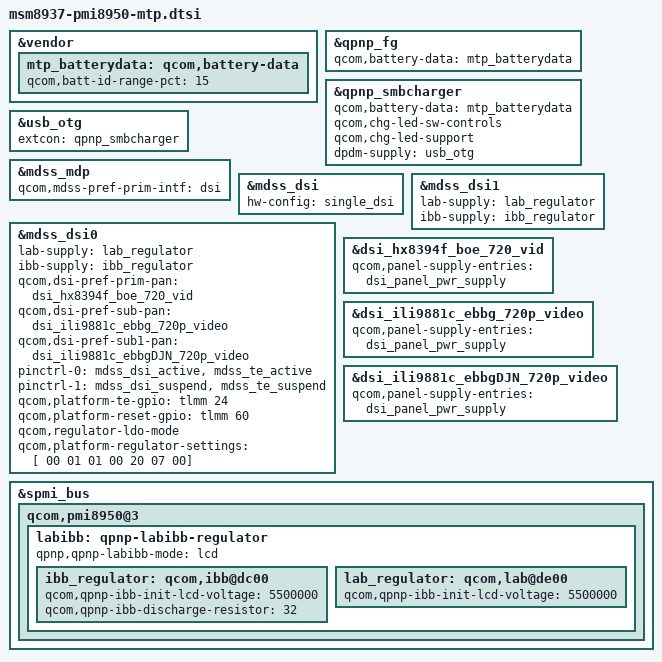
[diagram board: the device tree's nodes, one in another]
/*
 * Copyright (c) 2015-2016, 2018, The Linux Foundation. All rights reserved.
 * Copyright (C) 2018 XiaoMi, Inc.
 *
 * This program is free software; you can redistribute it and/or modify
 * it under the terms of the GNU General Public License version 2 and
 * only version 2 as published by the Free Software Foundation.
 *
 * This program is distributed in the hope that it will be useful,
 * but WITHOUT ANY WARRANTY; without even the implied warranty of
 * MERCHANTABILITY or FITNESS FOR A PARTICULAR PURPOSE.  See the
 * GNU General Public License for more details.
 */

#include "pmi8950.dtsi"
#include "msm8937-mtp.dtsi"
#include "dsi-panel-hx8394f-boe-720p-video.dtsi"
#include "dsi-panel-ili9881c-ebbg-720p-video.dtsi"
#include "dsi-panel-ili9881c-ebbgDJN-720p-video.dtsi"

&vendor {
	mtp_batterydata: qcom,battery-data {
		qcom,batt-id-range-pct = <15>;
		#include "batterydata-itech-3000mah.dtsi"
		#include "batterydata-ascent-3450mAh.dtsi"
	};
};

&qpnp_fg {
	qcom,battery-data = <&mtp_batterydata>;
};

&qpnp_smbcharger {
	qcom,battery-data = <&mtp_batterydata>;
	qcom,chg-led-sw-controls;
	qcom,chg-led-support;
	dpdm-supply = <&usb_otg>;
};

&usb_otg {
	extcon = <&qpnp_smbcharger>;
};

&labibb {
	status = "ok";
	qpnp,qpnp-labibb-mode = "lcd";
};

&ibb_regulator {
	qcom,qpnp-ibb-discharge-resistor = <32>;
};

&mdss_mdp {
	qcom,mdss-pref-prim-intf = "dsi";
};

&mdss_dsi {
	hw-config = "single_dsi";
};

&mdss_dsi0 {
	lab-supply = <&lab_regulator>;
	ibb-supply = <&ibb_regulator>;
	
	qcom,dsi-pref-prim-pan = <&dsi_hx8394f_boe_720_vid>;
	qcom,dsi-pref-sub-pan = <&dsi_ili9881c_ebbg_720p_video>;
	qcom,dsi-pref-sub1-pan = <&dsi_ili9881c_ebbgDJN_720p_video>;
	pinctrl-names = "mdss_default", "mdss_sleep";
	pinctrl-0 = <&mdss_dsi_active &mdss_te_active>;
	pinctrl-1 = <&mdss_dsi_suspend &mdss_te_suspend>;

	qcom,platform-te-gpio = <&tlmm 24 0>;
	qcom,platform-reset-gpio = <&tlmm 60 0>;

	qcom,regulator-ldo-mode;
	qcom,platform-regulator-settings = [ 00 01 01 00 20 07 00];
};

&mdss_dsi1 {
	lab-supply = <&lab_regulator>;
	ibb-supply = <&ibb_regulator>;
};

&dsi_hx8394f_boe_720_vid {
	qcom,panel-supply-entries = <&dsi_panel_pwr_supply>;
};

&dsi_ili9881c_ebbg_720p_video {
	qcom,panel-supply-entries = <&dsi_panel_pwr_supply>;
};
&dsi_ili9881c_ebbgDJN_720p_video {
	qcom,panel-supply-entries = <&dsi_panel_pwr_supply>;
};

&spmi_bus {
	qcom,pmi8950@3 {
		labibb: qpnp-labibb-regulator {
			ibb_regulator: qcom,ibb@dc00 {
				/delete-property/
					qcom,qpnp-ibb-use-default-voltage;
				qcom,qpnp-ibb-init-lcd-voltage = <5500000>;
			};

			lab_regulator: qcom,lab@de00 {
				/delete-property/
					qcom,qpnp-ibb-use-default-voltage;
				qcom,qpnp-ibb-init-lcd-voltage = <5500000>;
			};
		};
	};
};
